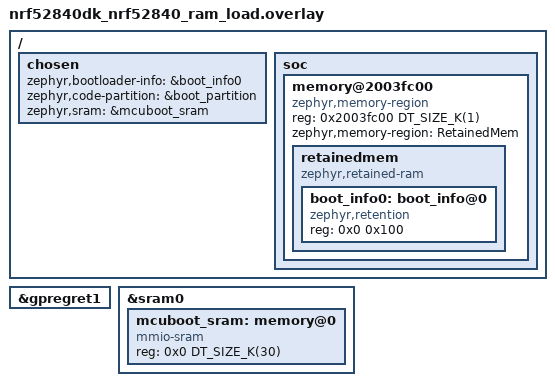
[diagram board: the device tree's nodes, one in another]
&gpregret1 {
	/delete-node/ boot_mode@0;
};

/ {
	chosen {
		/delete-property/ zephyr,boot-mode;
		zephyr,bootloader-info = &boot_info0;
		zephyr,code-partition = &boot_partition;
		zephyr,sram = &mcuboot_sram;
	};

	soc {
		memory@2003fc00 {
			compatible = "zephyr,memory-region", "mmio-sram";
			reg = <0x2003fc00 DT_SIZE_K(1)>;
			ranges = <0x0 0x2003fc00 DT_SIZE_K(1)>;
			zephyr,memory-region = "RetainedMem";
			status = "okay";
			#address-cells = <1>;
			#size-cells = <1>;

			retainedmem {
				compatible = "zephyr,retained-ram";
				status = "okay";
				ranges;
				#address-cells = <1>;
				#size-cells = <1>;

				boot_info0: boot_info@0 {
					compatible = "zephyr,retention";
					status = "okay";
					reg = <0x0 0x100>;
				};
			};
		};
	};
};

&sram0 {
	mcuboot_sram: memory@0 {
		compatible = "mmio-sram";
		reg = <0x0 DT_SIZE_K(30)>;
	};
};
